# CY8C5888LTI_LP097 register map
File version: 0.1
CY8C58LP
Registers are 8-bit, read-write, no defined reset value unless marked. A register's access mark holds for its fields unless they carry their own. Offsets are from the block's base; lines under a group give offsets from that group; [hi:lo] are bit positions; {n}, {i} and the like mark numbered series; 'fields as' and 'values as' point back to an identical list; <NAME> marks a mode.

## Memory map
0x00000000 Vis_H_1
0x00000000 Vis_H_2
0x00000000 Vis_L_2
0x00000000 Vis_H
0x00000000 Vis_L
0x00000000 ClockCountSel
0x00000000 Vis_H_3
0x00000000 Vis_L_3
0x00000000 ClockCounter
0x00000000 USBUART — USBFS
0x00000000 ConsolePort_2_ClockTimer
0x00000000 ConsolePort_2_Control_Reg_1
0x00000000 ConsolePort_2_WinTimer
0x00000000 Vis_L_1
0x00000000 ConsolePort_1_ClockTimer
0x00000000 ConsolePort_1_Control_Reg_1
0x00000000 ConsolePort_1_WinTimer

## Vis_H_1
Base 0x00000000
0x40006575 Vis_H_1_CONTROL_REG

## Vis_H_2
Base 0x00000000
0x40006576 Vis_H_2_CONTROL_REG

## Vis_L_2
Base 0x00000000
0x40006475 Vis_L_2_CONTROL_REG

## Vis_H
Base 0x00000000
0x40006578 Vis_H_CONTROL_REG

## Vis_L
Base 0x00000000
0x40006476 Vis_L_CONTROL_REG

## ClockCountSel
Base 0x00000000
0x4000647E ClockCountSel_CONTROL_REG

## Vis_H_3
Base 0x00000000
0x40006473 Vis_H_3_CONTROL_REG

## Vis_L_3
Base 0x00000000
0x40006470 Vis_L_3_CONTROL_REG

## ClockCounter
Base 0x00000000
0x40006407 ClockCounter_COUNTER — UDB.A0 - Current Counter Value
0x40006427 ClockCounter_PERIOD — UDB.D0 - Assigned Period
0x40006437 ClockCounter_COMPARE — UDB.D1 - Assigned Compare Value
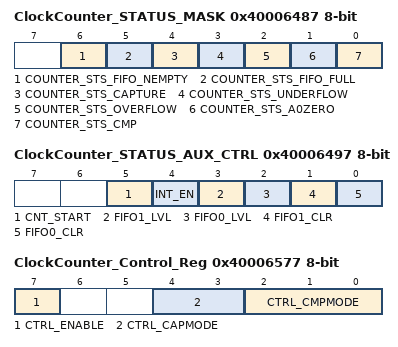
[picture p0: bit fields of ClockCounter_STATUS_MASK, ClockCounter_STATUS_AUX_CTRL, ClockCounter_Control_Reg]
0x40006487 ClockCounter_STATUS_MASK — UDB Status bits Interrupt Mask Enable Register
  [6] COUNTER_STS_FIFO_NEMPTY — FIFO Not Empty Status
  [5] COUNTER_STS_FIFO_FULL — FIFO Full Status
  [4] COUNTER_STS_CAPTURE — Capture Status
  [3] COUNTER_STS_UNDERFLOW — Underflow status
  [2] COUNTER_STS_OVERFLOW — Overflow status
  [1] COUNTER_STS_A0ZERO — A0 Zero ouput status
  [0] COUNTER_STS_CMP — Compare output status
0x40006497 ClockCounter_STATUS_AUX_CTRL — UDB Auxilliary Control Register
  [5] CNT_START — FIFO0 clear
    0=E_CNT_START0 (Disable counter); 1=E_CNT_START1 (Enable counter)
  [4] INT_EN
    0=E_INT_EN0 (Interrupt disabled); 1=E_INT_EN1 (Interrupt enabled)
  [3] FIFO1_LVL — FIFO level
    0=E_FIFO_LVL_0 (FIFO LVL: input mode: FIFO not full; output mode: FIFO not empty); 1=E_FIFO_LVL_1 (FIFO LVL: input mode: FIFO at least 1/2 empty; output mode: FIFO at least 1/2 full)
  [2] FIFO0_LVL — FIFO level
    values as FIFO1_LVL
  [1] FIFO1_CLR — FIFO1 clear
    0=E_FIFO_CLR_0 (Normal FIFO operation); 1=E_FIFO_CLR_1 (Clear FIFO state)
  [0] FIFO0_CLR — FIFO0 clear
    values as FIFO1_CLR
0x40006577 ClockCounter_Control_Reg — UDB Control Register - Assigned Control Register Value
  [7] CTRL_ENABLE — Enable Counter
  [4:3] CTRL_CAPMODE — Capture mode
  [2:0] CTRL_CMPMODE — Compare mode

## ConsolePort_2_ClockTimer
Base 0x00000000
0x40006408 ConsolePort_2_ClockTimer_COUNTER — UDB.A0 - Current Down Counter Value
0x40006428 ConsolePort_2_ClockTimer_PERIOD — UDB.D0 - Assigned Period
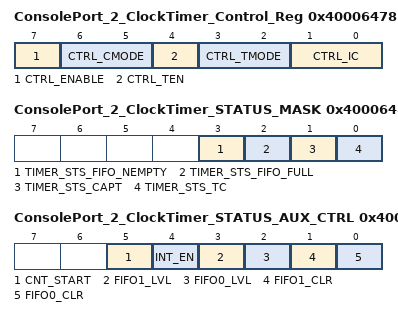
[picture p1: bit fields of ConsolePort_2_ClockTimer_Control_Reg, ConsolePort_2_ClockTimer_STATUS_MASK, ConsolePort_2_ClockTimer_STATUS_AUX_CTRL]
0x40006478 ConsolePort_2_ClockTimer_Control_Reg — UDB Control Register - Assigned Control Register Value
  [7] CTRL_ENABLE — Enable the Timer
  [6:5] CTRL_CMODE — Capture Mode
  [4] CTRL_TEN — Trigger Enable Bit
  [3:2] CTRL_TMODE — Trigger Mode
  [1:0] CTRL_IC — Interrupt Count
0x40006488 ConsolePort_2_ClockTimer_STATUS_MASK — UDB Status bits Interrupt Mask Enable Register
  [3] TIMER_STS_FIFO_NEMPTY ro — FIFO Empty status
  [2] TIMER_STS_FIFO_FULL ro — FIFO Full Status
  [1] TIMER_STS_CAPT ro — Enables the Interrupt on Capture
  [0] TIMER_STS_TC ro — Enables the Interrupt on TC
0x40006498 ConsolePort_2_ClockTimer_STATUS_AUX_CTRL — UDB Auxilliary Control Register
  [5] CNT_START — FIFO0 clear
    0=E_CNT_START0 (Disable counter); 1=E_CNT_START1 (Enable counter)
  [4] INT_EN
    0=E_INT_EN0 (Interrupt disabled); 1=E_INT_EN1 (Interrupt enabled)
  [3] FIFO1_LVL — FIFO level
    0=E_FIFO_LVL_0 (FIFO LVL: input mode: FIFO not full; output mode: FIFO not empty); 1=E_FIFO_LVL_1 (FIFO LVL: input mode: FIFO at least 1/2 empty; output mode: FIFO at least 1/2 full)
  [2] FIFO0_LVL — FIFO level
    values as FIFO1_LVL
  [1] FIFO1_CLR — FIFO1 clear
    0=E_FIFO_CLR_0 (Normal FIFO operation); 1=E_FIFO_CLR_1 (Clear FIFO state)
  [0] FIFO0_CLR — FIFO0 clear
    values as FIFO1_CLR
